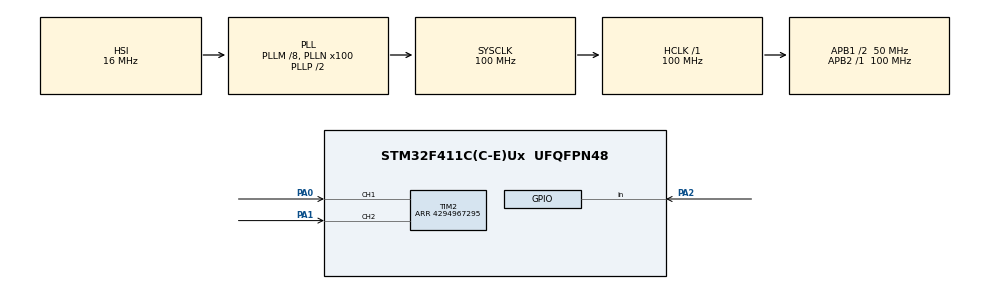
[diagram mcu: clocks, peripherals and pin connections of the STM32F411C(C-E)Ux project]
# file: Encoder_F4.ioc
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Mcu.Family=STM32F4
Mcu.Name=STM32F411C(C-E)Ux
Mcu.Package=UFQFPN48
NVIC.PriorityGroup=NVIC_PRIORITYGROUP_4
PA0-WKUP.Signal=S_TIM2_CH1_ETR
PA1.Signal=S_TIM2_CH2
PA13.Mode=Serial_Wire
PA13.Signal=SYS_JTMS-SWDIO
PA14.Mode=Serial_Wire
PA14.Signal=SYS_JTCK-SWCLK
PA2.Signal=GPIO_Input
PH0\ -\ OSC_IN.Mode=HSE-External-Oscillator
PH0\ -\ OSC_IN.Signal=RCC_OSC_IN
PH1\ -\ OSC_OUT.Mode=HSE-External-Oscillator
PH1\ -\ OSC_OUT.Signal=RCC_OSC_OUT
ProjectManager.HeapSize=0x200
ProjectManager.StackSize=0x400
ProjectManager.TargetToolchain=STM32CubeIDE
RCC.48MHZClocksFreq_Value=50000000
RCC.AHBFreq_Value=100000000
RCC.APB1CLKDivider=RCC_HCLK_DIV2
RCC.APB1Freq_Value=50000000
RCC.APB1TimFreq_Value=100000000
RCC.APB2Freq_Value=100000000
RCC.APB2TimFreq_Value=100000000
RCC.CortexFreq_Value=100000000
RCC.HCLKFreq_Value=100000000
RCC.HSE_VALUE=25000000
RCC.HSI_VALUE=16000000
RCC.LSE_VALUE=32768
RCC.PLLM=8
RCC.PLLN=100
RCC.SYSCLKFreq_VALUE=100000000
RCC.SYSCLKSource=RCC_SYSCLKSOURCE_PLLCLK
RCC.VCOOutputFreq_Value=200000000
SH.S_TIM2_CH1_ETR.0=TIM2_CH1,Encoder_Interface
SH.S_TIM2_CH2.0=TIM2_CH2,Encoder_Interface
TIM2.EncoderMode=TIM_ENCODERMODE_TI12
TIM2.IC1Filter=10
TIM2.IC2Filter=10
TIM2.Period=4294967295
board=custom

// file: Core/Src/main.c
/* USER CODE BEGIN Header */
/**
  ******************************************************************************
  * @file           : main.c
  * @brief          : Main program body
  ******************************************************************************
  * @attention
  *
  * Copyright (c) 2023 STMicroelectronics.
  * All rights reserved.
  *
  * This software is licensed under terms that can be found in the LICENSE file
  * in the root directory of this software component.
  * If no LICENSE file comes with this software, it is provided AS-IS.
  *
  ******************************************************************************
  */
/* USER CODE END Header */
#include "main.h"

TIM_HandleTypeDef htim2;

/* USER CODE BEGIN PV */
int32_t rate = 0;
/* USER CODE END PV */

void SystemClock_Config(void);
static void MX_GPIO_Init(void);
static void MX_TIM2_Init(void);

int main(void)
{

  /* MCU Configuration--------------------------------------------------------*/

  /* Reset of all peripherals, Initializes the Flash interface and the Systick. */
  HAL_Init();

  /* Configure the system clock */
  SystemClock_Config();

  /* Initialize all configured peripherals */
  MX_GPIO_Init();
  MX_TIM2_Init();
  /* USER CODE BEGIN 2 */
  HAL_TIM_Encoder_Start(&htim2, TIM_CHANNEL_ALL);
  /* USER CODE END 2 */

  /* Infinite loop */
  while (1)
  {

    /* USER CODE BEGIN 3 */
	  rate = TIM2->CNT >> 4;
  }
  /* USER CODE END 3 */
}

void SystemClock_Config(void)
{
  RCC_OscInitTypeDef RCC_OscInitStruct = {0};
  RCC_ClkInitTypeDef RCC_ClkInitStruct = {0};

  /** Configure the main internal regulator output voltage
  */
  __HAL_RCC_PWR_CLK_ENABLE();
  __HAL_PWR_VOLTAGESCALING_CONFIG(PWR_REGULATOR_VOLTAGE_SCALE1);

  /** Initializes the RCC Oscillators according to the specified parameters
  * in the RCC_OscInitTypeDef structure.
  */
  RCC_OscInitStruct.OscillatorType = RCC_OSCILLATORTYPE_HSI;
  RCC_OscInitStruct.HSIState = RCC_HSI_ON;
  RCC_OscInitStruct.HSICalibrationValue = RCC_HSICALIBRATION_DEFAULT;
  RCC_OscInitStruct.PLL.PLLState = RCC_PLL_ON;
  RCC_OscInitStruct.PLL.PLLSource = RCC_PLLSOURCE_HSI;
  RCC_OscInitStruct.PLL.PLLM = 8;
  RCC_OscInitStruct.PLL.PLLN = 100;
  RCC_OscInitStruct.PLL.PLLP = RCC_PLLP_DIV2;
  RCC_OscInitStruct.PLL.PLLQ = 4;
  if (HAL_RCC_OscConfig(&RCC_OscInitStruct) != HAL_OK)
  {
    Error_Handler();
  }

  /** Initializes the CPU, AHB and APB buses clocks
  */
  RCC_ClkInitStruct.ClockType = RCC_CLOCKTYPE_HCLK|RCC_CLOCKTYPE_SYSCLK
                              |RCC_CLOCKTYPE_PCLK1|RCC_CLOCKTYPE_PCLK2;
  RCC_ClkInitStruct.SYSCLKSource = RCC_SYSCLKSOURCE_PLLCLK;
  RCC_ClkInitStruct.AHBCLKDivider = RCC_SYSCLK_DIV1;
  RCC_ClkInitStruct.APB1CLKDivider = RCC_HCLK_DIV2;
  RCC_ClkInitStruct.APB2CLKDivider = RCC_HCLK_DIV1;

  if (HAL_RCC_ClockConfig(&RCC_ClkInitStruct, FLASH_LATENCY_3) != HAL_OK)
  {
    Error_Handler();
  }
}

static void MX_TIM2_Init(void)
{

  TIM_Encoder_InitTypeDef sConfig = {0};
  TIM_MasterConfigTypeDef sMasterConfig = {0};

  htim2.Instance = TIM2;
  htim2.Init.Prescaler = 0;
  htim2.Init.CounterMode = TIM_COUNTERMODE_UP;
  htim2.Init.Period = 4294967295;
  htim2.Init.ClockDivision = TIM_CLOCKDIVISION_DIV1;
  htim2.Init.AutoReloadPreload = TIM_AUTORELOAD_PRELOAD_DISABLE;
  sConfig.EncoderMode = TIM_ENCODERMODE_TI12;
  sConfig.IC1Polarity = TIM_ICPOLARITY_RISING;
  sConfig.IC1Selection = TIM_ICSELECTION_DIRECTTI;
  sConfig.IC1Prescaler = TIM_ICPSC_DIV1;
  sConfig.IC1Filter = 10;
  sConfig.IC2Polarity = TIM_ICPOLARITY_RISING;
  sConfig.IC2Selection = TIM_ICSELECTION_DIRECTTI;
  sConfig.IC2Prescaler = TIM_ICPSC_DIV1;
  sConfig.IC2Filter = 10;
  if (HAL_TIM_Encoder_Init(&htim2, &sConfig) != HAL_OK)
  {
    Error_Handler();
  }
  sMasterConfig.MasterOutputTrigger = TIM_TRGO_RESET;
  sMasterConfig.MasterSlaveMode = TIM_MASTERSLAVEMODE_DISABLE;
  if (HAL_TIMEx_MasterConfigSynchronization(&htim2, &sMasterConfig) != HAL_OK)
  {
    Error_Handler();
  }

}

static void MX_GPIO_Init(void)
{
  GPIO_InitTypeDef GPIO_InitStruct = {0};

  /* GPIO Ports Clock Enable */
  __HAL_RCC_GPIOH_CLK_ENABLE();
  __HAL_RCC_GPIOA_CLK_ENABLE();

  /*Configure GPIO pin : PA2 */
  GPIO_InitStruct.Pin = GPIO_PIN_2;
  GPIO_InitStruct.Mode = GPIO_MODE_INPUT;
  GPIO_InitStruct.Pull = GPIO_NOPULL;
  HAL_GPIO_Init(GPIOA, &GPIO_InitStruct);

}

void Error_Handler(void)
{
  __disable_irq();
  while (1)
  {
  }
}
